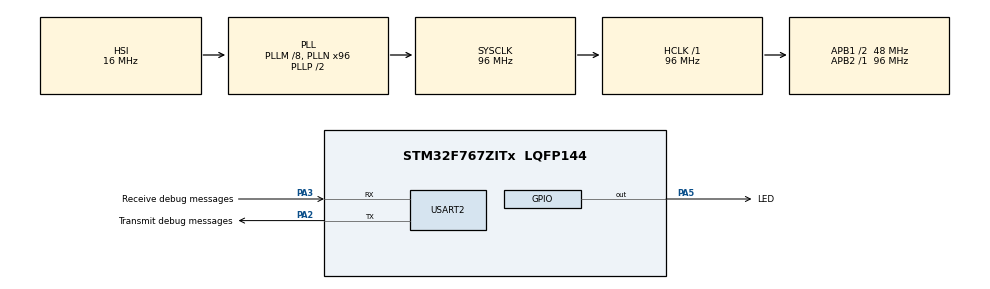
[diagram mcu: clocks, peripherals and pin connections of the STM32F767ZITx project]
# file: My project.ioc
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Mcu.Family=STM32F7
Mcu.Name=STM32F767ZITx
Mcu.Package=LQFP144
NVIC.PriorityGroup=NVIC_PRIORITYGROUP_4
PA2.GPIO_Label=Transmit debug messages 
PA2.Mode=Asynchronous
PA2.Signal=USART2_TX
PA3.GPIO_Label=Receive debug messages 
PA3.Mode=Asynchronous
PA3.Signal=USART2_RX
PA5.GPIO_Label=LED
PA5.GPIO_Speed=GPIO_SPEED_FREQ_VERY_HIGH
PA5.Signal=GPIO_Output
ProjectManager.HeapSize=0x200
ProjectManager.StackSize=0x400
ProjectManager.TargetToolchain=STM32CubeIDE
RCC.48MHZClocksFreq_Value=24000000
RCC.AHBFreq_Value=96000000
RCC.APB1CLKDivider=RCC_HCLK_DIV2
RCC.APB1Freq_Value=48000000
RCC.APB1TimFreq_Value=96000000
RCC.APB2Freq_Value=96000000
RCC.APB2TimFreq_Value=96000000
RCC.CortexFreq_Value=96000000
RCC.HCLKFreq_Value=96000000
RCC.HSE_VALUE=8000000
RCC.HSI_VALUE=16000000
RCC.LSE_VALUE=32768
RCC.PLLM=8
RCC.PLLMUL=RCC_PLL_MUL9
RCC.PLLN=96
RCC.PLLQ=4
RCC.PRESCALERUSB=RCC_USBCLKSOURCE_PLL_DIV1_5
RCC.SYSCLKFreq_VALUE=96000000
RCC.SYSCLKSource=RCC_SYSCLKSOURCE_PLLCLK
RCC.SYSCLKSourceVirtual=RCC_SYSCLKSOURCE_PLLCLK
RCC.USBFreq_Value=48000000
RCC.VCOOutputFreq_Value=192000000
USART2.VirtualMode-Asynchronous=VM_ASYNC
board=NUCLEO-F767ZI

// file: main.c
/* USER CODE BEGIN Header */
/**
  ******************************************************************************
  * @file           : main.c
  * @brief          : Main program body
  ******************************************************************************
  * @attention
  *
  * Copyright (c) 2024 STMicroelectronics.
  * All rights reserved.
  *
  * This software is licensed under terms that can be found in the LICENSE file
  * in the root directory of this software component.
  * If no LICENSE file comes with this software, it is provided AS-IS.
  *
  ******************************************************************************
  */
/* USER CODE END Header */
#include "main.h"
#include "usart.h"
#include "gpio.h"

void SystemClock_Config(void);

int main(void)
{

  /* MCU Configuration--------------------------------------------------------*/

  /* Reset of all peripherals, Initializes the Flash interface and the Systick. */
  HAL_Init();

  /* Configure the system clock */
  SystemClock_Config();

  /* Initialize all configured peripherals */
  MX_GPIO_Init();
  MX_USART2_UART_Init();
  /* USER CODE BEGIN 2 */

  // Transmit an initial debug message
  char initMsg[] = "System Initialized.\r\n";
  HAL_UART_Transmit(&huart2, (uint8_t*)initMsg, sizeof(initMsg) - 1, HAL_MAX_DELAY);

  /* USER CODE END 2 */

  /* Infinite loop */
  while (1)
  {

    /* USER CODE BEGIN 3 */

    // Toggle the LED connected to PA5
    HAL_GPIO_TogglePin(GPIOA, GPIO_PIN_5);

    // Transmit a debug message over UART
    char msg[] = "LED Toggled\r\n";
    HAL_UART_Transmit(&huart2, (uint8_t*)msg, sizeof(msg) - 1, HAL_MAX_DELAY);

    // Add a delay of 500ms
    HAL_Delay(500);
  }
  /* USER CODE END 3 */
}

void SystemClock_Config(void)
{
  RCC_OscInitTypeDef RCC_OscInitStruct = {0};
  RCC_ClkInitTypeDef RCC_ClkInitStruct = {0};

  /** Configure the main internal regulator output voltage
  */
  __HAL_RCC_PWR_CLK_ENABLE();
  __HAL_PWR_VOLTAGESCALING_CONFIG(PWR_REGULATOR_VOLTAGE_SCALE3);

  /** Initializes the RCC Oscillators according to the specified parameters
  * in the RCC_OscInitTypeDef structure.
  */
  RCC_OscInitStruct.OscillatorType = RCC_OSCILLATORTYPE_HSI;
  RCC_OscInitStruct.HSIState = RCC_HSI_ON;
  RCC_OscInitStruct.HSICalibrationValue = RCC_HSICALIBRATION_DEFAULT;
  RCC_OscInitStruct.PLL.PLLState = RCC_PLL_ON;
  RCC_OscInitStruct.PLL.PLLSource = RCC_PLLSOURCE_HSI;
  RCC_OscInitStruct.PLL.PLLM = 8;
  RCC_OscInitStruct.PLL.PLLN = 96;
  RCC_OscInitStruct.PLL.PLLP = RCC_PLLP_DIV2;
  RCC_OscInitStruct.PLL.PLLQ = 4;
  RCC_OscInitStruct.PLL.PLLR = 2;
  if (HAL_RCC_OscConfig(&RCC_OscInitStruct) != HAL_OK)
  {
    Error_Handler();
  }

  /** Activate the Over-Drive mode
  */
  if (HAL_PWREx_EnableOverDrive() != HAL_OK)
  {
    Error_Handler();
  }

  /** Initializes the CPU, AHB and APB buses clocks
  */
  RCC_ClkInitStruct.ClockType = RCC_CLOCKTYPE_HCLK|RCC_CLOCKTYPE_SYSCLK
                              |RCC_CLOCKTYPE_PCLK1|RCC_CLOCKTYPE_PCLK2;
  RCC_ClkInitStruct.SYSCLKSource = RCC_SYSCLKSOURCE_PLLCLK;
  RCC_ClkInitStruct.AHBCLKDivider = RCC_SYSCLK_DIV1;
  RCC_ClkInitStruct.APB1CLKDivider = RCC_HCLK_DIV2;
  RCC_ClkInitStruct.APB2CLKDivider = RCC_HCLK_DIV1;

  if (HAL_RCC_ClockConfig(&RCC_ClkInitStruct, FLASH_LATENCY_3) != HAL_OK)
  {
    Error_Handler();
  }
}

void Error_Handler(void)
{
  __disable_irq();
  while (1)
  {
  }
}
